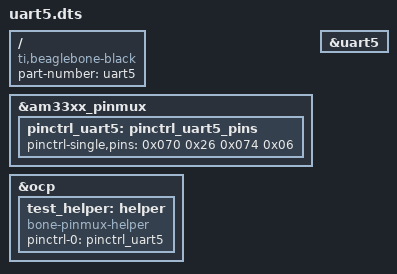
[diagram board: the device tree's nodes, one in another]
/dts-v1/;
/plugin/;

/{
   compatible = "ti,beaglebone-black";
   part-number = "uart5";
  
   fragment@0 {
	target = <&am33xx_pinmux>;
	__overlay__ {
	   pinctrl_uart5: pinctrl_uart5_pins {
		pinctrl-single,pins= <
		   0x070 0x26
		   0x074 0x06
		>;
	   };
	};
   };

   fragment@1 {
	target = <&uart5>;
	__overlay__ {
		status = "okay";
	};
   };

   fragment@2 {
	target = <&ocp>;
	__overlay__ {
	   test_helper: helper {
		compatible = "bone-pinmux-helper";
		pinctrl-names = "default";
		pinctrl-0 = <&pinctrl_uart5>;
		status = "okay";
	   };
	};
   };
};
